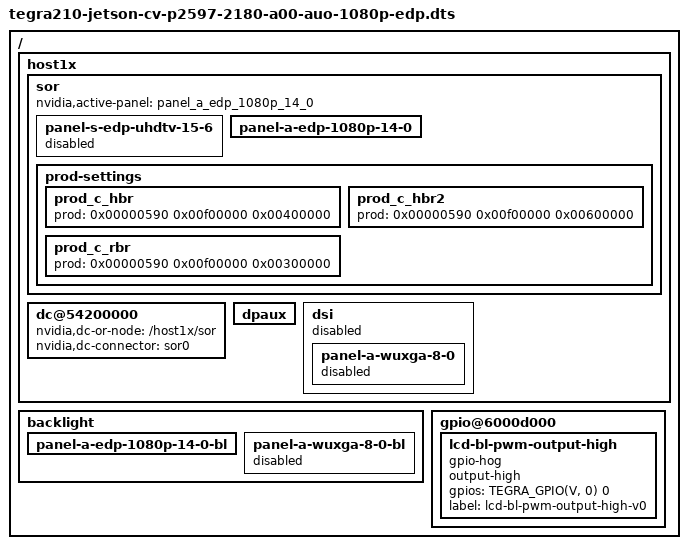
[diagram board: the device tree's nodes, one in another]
/*
* Copyright (c) 2015-2017, NVIDIA CORPORATION.  All rights reserved.
*
* This program is free software; you can redistribute it and/or modify
* it under the terms of the GNU General Public License as published by
* the Free Software Foundation; version 2 of the License.
*
* This program is distributed in the hope that it will be useful, but WITHOUT
* ANY WARRANTY; without even the implied warranty of MERCHANTABILITY or
* FITNESS FOR A PARTICULAR PURPOSE.  See the GNU General Public License for
* more details.
*
* You should have received a copy of the GNU General Public License along
* with this program; if not, write to the Free Software Foundation, Inc.,
* 51 Franklin Street, Fifth Floor, Boston, MA  02110-1301, USA.
*
*/
#include "tegra210-jetson-cv-base-p2597-2180-a00.dts"

/ {
	host1x {
		sor {
			status = "okay";
			nvidia,active-panel = <&panel_a_edp_1080p_14_0>;
			panel-s-edp-uhdtv-15-6 {
				status = "disabled";
			};
			panel-a-edp-1080p-14-0 {
				status = "okay";
			};
			prod-settings {
				prod_c_hbr {
					prod = <
						0x00000590 0x00f00000 0x00400000   //SOR_NV_PDISP_SOR_PLL1_0	23:20=LOADADJ	0x04 
						>;
				};
				prod_c_hbr2 {
					prod = <
						0x00000590 0x00f00000 0x00600000   //SOR_NV_PDISP_SOR_PLL1_0	23:20=LOADADJ	0x06 
						>;
				};
				prod_c_rbr {
					prod = <
						0x00000590 0x00f00000 0x00300000   //SOR_NV_PDISP_SOR_PLL1_0	23:20=LOADADJ	0x03
						>;
				};

			};
		};

		dc@54200000 {
			nvidia,dc-or-node = "/host1x/sor";
			nvidia,dc-connector = <&sor0>;
		};
		dpaux {
			status = "okay";
		};
		dsi {
			status = "disabled";
			panel-a-wuxga-8-0 {
				status = "disabled";
			};
		};
	};

	backlight {
		panel-a-edp-1080p-14-0-bl {
			status = "okay";
		};
		panel-a-wuxga-8-0-bl {
			status = "disabled";
		};
	};
	gpio@6000d000 {
		lcd-bl-pwm-output-high {
		gpio-hog;
		output-high;
		gpios = <
			TEGRA_GPIO(V, 0) 0
			>;
		label = "lcd-bl-pwm-output-high-v0";
		};
	};
};
